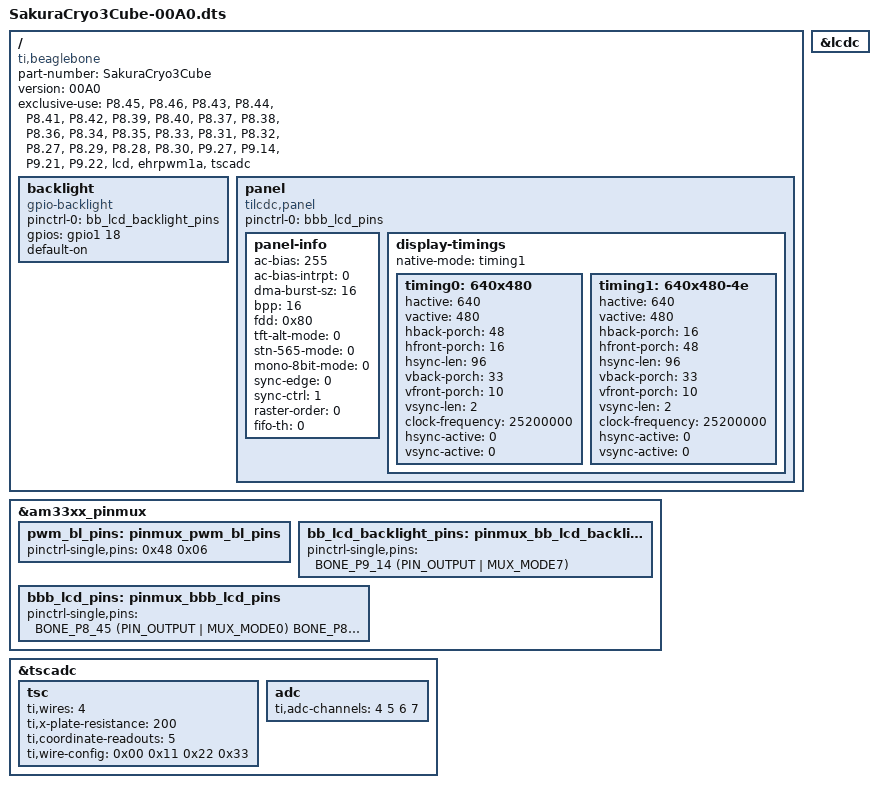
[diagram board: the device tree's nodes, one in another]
/*
 * Copyright (C) 2014 Sakura Finetek Inc.
 *
 * This program is free software; you can redistribute it and/or modify
 * it under the terms of the GNU General Public License version 2 as
 * published by the Free Software Foundation.
 */
/dts-v1/;
/plugin/;

#include <dt-bindings/board/am335x-bbw-bbb-base.h>
#include <dt-bindings/gpio/gpio.h>
#include <dt-bindings/pinctrl/am33xx.h>

/ {
	compatible = "ti,beaglebone", "ti,beaglebone-black";

	/* identification */
	part-number = "SakuraCryo3Cube";
	version = "00A0";

	/* state the resources this cape uses */
	exclusive-use =
		/* the pin header uses */
		"P8.45",	/* lcd: lcd_data0 */
		"P8.46",	/* lcd: lcd_data1 */
		"P8.43",	/* lcd: lcd_data2 */
		"P8.44",	/* lcd: lcd_data3 */
		"P8.41",	/* lcd: lcd_data4 */
		"P8.42",	/* lcd: lcd_data5 */
		"P8.39",	/* lcd: lcd_data6 */
		"P8.40",	/* lcd: lcd_data7 */
		"P8.37",	/* lcd: lcd_data8 */
		"P8.38",	/* lcd: lcd_data9 */
		"P8.36",	/* lcd: lcd_data10 */
		"P8.34",	/* lcd: lcd_data11 */
		"P8.35",	/* lcd: lcd_data12 */
		"P8.33",	/* lcd: lcd_data13 */
		"P8.31",	/* lcd: lcd_data14 */
		"P8.32",	/* lcd: lcd_data15 */
		"P8.27",	/* lcd: lcd_vsync */
		"P8.29",	/* lcd: lcd_hsync */
		"P8.28",	/* lcd: lcd_pclk */
		"P8.30",	/* lcd: lcd_ac_bias_en */
		"P9.27",	/* lcd: lcd_disen */
		"P9.14",	/* pwm: ehrpwm1a */
		"P9.21",	/* uart2_txd */
		"P9.22",	/* uart2_rxd */
		/* the hardware ip uses */
		"lcd",
		"ehrpwm1a",
		"tscadc";

	fragment@0 {
		target = <&am33xx_pinmux>;
		__overlay__ {
			pwm_bl_pins: pinmux_pwm_bl_pins {
				pinctrl-single,pins = <
					0x48 0x06       /* gpmc_a2.ehrpwm1a, OMAP_MUX_MODE6 | AM33XX_PIN_OUTPUT */
				>;
			};

			bb_lcd_backlight_pins: pinmux_bb_lcd_backlight_pins {
				pinctrl-single,pins = <
					BONE_P9_14 (PIN_OUTPUT | MUX_MODE7) /* gpmc_a[2].GPIO1[18] (backlight control) */
				>;
			};

			bbb_lcd_pins: pinmux_bbb_lcd_pins {
				pinctrl-single,pins = <
					BONE_P8_45 (PIN_OUTPUT | MUX_MODE0) /* lcd_data0.lcd_data0 */
					BONE_P8_46 (PIN_OUTPUT | MUX_MODE0) /* lcd_data1.lcd_data1 */
					BONE_P8_43 (PIN_OUTPUT | MUX_MODE0) /* lcd_data2.lcd_data2 */
					BONE_P8_44 (PIN_OUTPUT | MUX_MODE0) /* lcd_data3.lcd_data3 */
					BONE_P8_41 (PIN_OUTPUT | MUX_MODE0) /* lcd_data4.lcd_data4 */
					BONE_P8_42 (PIN_OUTPUT | MUX_MODE0) /* lcd_data5.lcd_data5 */
					BONE_P8_39 (PIN_OUTPUT | MUX_MODE0) /* lcd_data6.lcd_data6 */
					BONE_P8_40 (PIN_OUTPUT | MUX_MODE0) /* lcd_data7.lcd_data7 */
					BONE_P8_37 (PIN_OUTPUT | MUX_MODE0) /* lcd_data8.lcd_data8 */
					BONE_P8_38 (PIN_OUTPUT | MUX_MODE0) /* lcd_data9.lcd_data9 */
					BONE_P8_36 (PIN_OUTPUT | MUX_MODE0) /* lcd_data10.lcd_data10 */
					BONE_P8_34 (PIN_OUTPUT | MUX_MODE0) /* lcd_data11.lcd_data11 */
					BONE_P8_35 (PIN_OUTPUT | MUX_MODE0) /* lcd_data12.lcd_data12 */
					BONE_P8_33 (PIN_OUTPUT | MUX_MODE0) /* lcd_data13.lcd_data13 */
					BONE_P8_31 (PIN_OUTPUT | MUX_MODE0) /* lcd_data14.lcd_data14 */
					BONE_P8_32 (PIN_OUTPUT | MUX_MODE0) /* lcd_data15.lcd_data15 */

					BONE_P8_27 (PIN_OUTPUT | MUX_MODE0) /* lcd_vsync.lcd_vsync */
					BONE_P8_29 (PIN_OUTPUT | MUX_MODE0) /* lcd_hsync.lcd_hsync */
					BONE_P8_28 (PIN_OUTPUT | MUX_MODE0) /* lcd_pclk.lcd_pclk */
					BONE_P8_30 (PIN_OUTPUT | MUX_MODE0) /* lcd_ac_bias_en.lcd_ac_bias_en */

					BONE_P9_27 (PIN_OUTPUT_PULLUP | MUX_MODE7) /* mcasp0_fsr.gpio3_19 */
				>;
			};

		};
	};

	fragment@1 {
		target-path="/";
		__overlay__ {

			/* avoid stupid warning */
			#address-cells = <1>;
			#size-cells = <1>;

			backlight {
				status = "okay";
				compatible = "gpio-backlight";
				pinctrl-names = "default";
				pinctrl-0 = <&bb_lcd_backlight_pins>;
				gpios = <&gpio1 18 GPIO_ACTIVE_HIGH>;
				default-on;
			};

/*			backlight { */
/*				compatible      = "pwm-backlight"; */
/*				pinctrl-names   = "default"; */
/*				pinctrl-0       = <&pwm_bl_pins>; */

/*				pwms = <&ehrpwm1 0 500000 0>; */
/*				pwm-names = "LCD4"; */
/*				brightness-levels = <0 1 2 3 4 5 6 7 8 9 10 11 12 13 14 15 16 17 18 19 20 21 22 23 24 25 26 27 28 29 30 31 32 33 34 35 36 37 38 39 40 41 42 43 44 45 46 47 48 49 50 51 52 53 54 55 56 57 58 59 60 61 62 63 64 65 66 67 68 69 70 71 72 73 74 75 76 77 78 79 80 81 82 83 84 85 86 87 88 89 90 91 92 93 94 95 96 97 98 99 100>; */
/*				default-brightness-level = <101>; */
/*				status = "okay"; */
/*			}; */


			/*
			From: Linux src: Documentation/devicetree/bindings/drm/tilcdc/panel.txt

			Device-Tree bindings for tilcdc DRM generic panel output driver

			Required properties:
			 - compatible: value should be "ti,tilcdc,panel".
			 - panel-info: configuration info to configure LCDC correctly for the panel
			   - ac-bias: AC Bias Pin Frequency
			   - ac-bias-intrpt: AC Bias Pin Transitions per Interrupt
			   - dma-burst-sz: DMA burst size
			   - bpp: Bits per pixel
			   - fdd: FIFO DMA Request Delay
			   - sync-edge: Horizontal and Vertical Sync Edge: 0=rising 1=falling
			   - sync-ctrl: Horizontal and Vertical Sync: Control: 0=ignore
			   - raster-order: Raster Data Order Select: 1=Most-to-least 0=Least-to-most
			   - fifo-th: DMA FIFO threshold
			 - display-timings: typical videomode of lcd panel.  Multiple video modes
			   can be listed if the panel supports multiple timings, but the 'native-mode'
			   should be the preferred/default resolution.  Refer to
			   Documentation/devicetree/bindings/video/display-timing.txt for display
			   timing binding details.

			Recommended properties:
			 - pinctrl-names, pinctrl-0: the pincontrol settings to configure
			   muxing properly for pins that connect to TFP410 device
			 */

			/* Recommended timings for ~60Hz 640x480
			   640x480 (0x4e)   25.2MHz -HSync -VSync
			         h: width   640 start  656 end  752 total  800 skew    0 clock   31.5KHz
			         v: height  480 start  490 end  492 total  525           clock   60.0Hz
			 */

			/* Settings for MTF-TV57NN721-AV */
			panel {
				status = "okay";
				compatible = "tilcdc,panel";
				pinctrl-names = "default";
				pinctrl-0 = <&bbb_lcd_pins>;
				panel-info {
					ac-bias           = <255>;
					ac-bias-intrpt    = <0>;
					dma-burst-sz      = <16>;
					bpp               = <16>;
					fdd	       = <0x80>;
					tft-alt-mode      = <0>;
					stn-565-mode      = <0>;
					mono-8bit-mode    = <0>;
					sync-edge         = <0>;
					sync-ctrl         = <1>;
					raster-order      = <0>;
					fifo-th           = <0>;
				};
				display-timings {
					native-mode = <&timing1>;
					timing0: 640x480 {   /* std PC VGA pixel clock should be 25175000 */
						hactive         = <640>;    /* active pixels */
						vactive         = <480>;    /* active lines */
						hback-porch     = <48>;     /* in pixels */
						hfront-porch    = <16>;
						hsync-len       = <96>;
						vback-porch     = <33>;     /* in lines */
						vfront-porch    = <10>;
						vsync-len       = <2>;
						clock-frequency = <25200000>;
						hsync-active    = <0>;      /* 0=low, 1=high, 2=ignored */
						vsync-active    = <0>;
					};
					timing1: 640x480-4e {
						hactive         = <640>;    /* active pixels */
						vactive         = <480>;    /* active lines */
						hback-porch     = <16>;     /* in pixels */
						hfront-porch    = <48>;
						hsync-len       = <96>;
						vback-porch     = <33>;     /* in lines */
						vfront-porch    = <10>;
						vsync-len       = <2>;
						clock-frequency = <25200000>;
						hsync-active    = <0>;      /* 0=low, 1=high, 2=ignored */
						vsync-active    = <0>;
					};
				};
			};
		};
	};

	fragment@2 {
		target = <&lcdc>;
		__overlay__ {
			status = "okay";
		};
	};

	fragment@3 {
		target = <&tscadc>;
		__overlay__ {

			status = "okay";
			tsc {
				ti,wires = <4>;
				ti,x-plate-resistance = <200>;
				ti,coordinate-readouts = <5>;
				ti,wire-config = <0x00 0x11 0x22 0x33>;
			};

			adc {
				ti,adc-channels = <4 5 6 7>;
			};
		};
	};

/* pws/pwm needs more testing.. */
/*	fragment@4 { */
/*		target = <&epwmss1>; */
/*		__overlay__ { */
/*			status = "okay"; */
/*		}; */
/* 	}; */

/*	fragment@5 {
/*		target = <&ehrpwm1>;
/*		__overlay__ {
/*			status = "okay"; */
/*		}; */
/*	}; */

};
